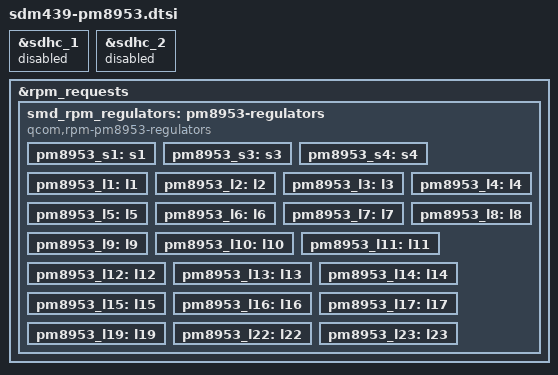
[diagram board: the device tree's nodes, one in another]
// SPDX-License-Identifier: GPL-2.0-only
#include "sdm439.dtsi"
#include "pm8953.dtsi"

&sdhc_1 {
	status = "disabled";
};

&sdhc_2 {
	status = "disabled";
};

&rpm_requests {
	smd_rpm_regulators: pm8953-regulators {
		compatible = "qcom,rpm-pm8953-regulators";

		pm8953_s1: s1 {};
		pm8953_s3: s3 {};
		pm8953_s4: s4 {};

		pm8953_l1: l1 {};
		pm8953_l2: l2 {};
		pm8953_l3: l3 {};
		pm8953_l4: l4 {};
		pm8953_l5: l5 {};
		pm8953_l6: l6 {};
		pm8953_l7: l7 {};
		pm8953_l8: l8 {};
		pm8953_l9: l9 {};
		pm8953_l10: l10 {};
		pm8953_l11: l11 {};
		pm8953_l12: l12 {};
		pm8953_l13: l13 {};
		pm8953_l14: l14 {};
		pm8953_l15: l15 {};
		pm8953_l16: l16 {};
		pm8953_l17: l17 {};
		pm8953_l19: l19 {};
		pm8953_l22: l22 {};
		pm8953_l23: l23 {};
	};
};

